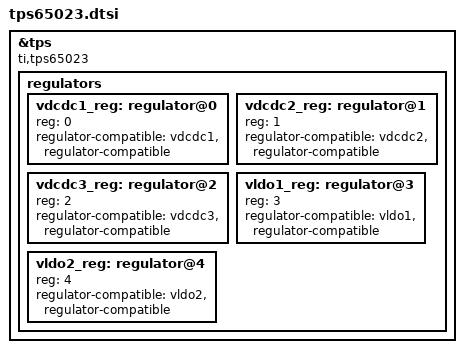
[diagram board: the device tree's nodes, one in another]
/*
 * Copyright (C) 2015 DENX Software GmbH Heiko Schocher <hs@denx.de>
 *
 * This program is free software; you can redistribute it and/or modify
 * it under the terms of the GNU General Public License version 2 as
 * published by the Free Software Foundation.
 */

/*
 * Integrated Power Management Chip
 * www.ti.com/lit/ds/symlink/tps65023.pdf
 */

&tps {
	compatible = "ti,tps65023";

	regulators {
		#address-cells = <1>;
		#size-cells = <0>;

		vdcdc1_reg: regulator@0 {
			reg = <0>;
			regulator-compatible = "vdcdc1", "regulator-compatible";
		};

		vdcdc2_reg: regulator@1 {
			reg = <1>;
			regulator-compatible = "vdcdc2", "regulator-compatible";
		};

		vdcdc3_reg: regulator@2 {
			reg = <2>;
			regulator-compatible = "vdcdc3", "regulator-compatible";
		};

		vldo1_reg: regulator@3 {
			reg = <3>;
			regulator-compatible = "vldo1", "regulator-compatible";
		};

		vldo2_reg: regulator@4 {
			reg = <4>;
			regulator-compatible = "vldo2", "regulator-compatible";
		};
	};
};
